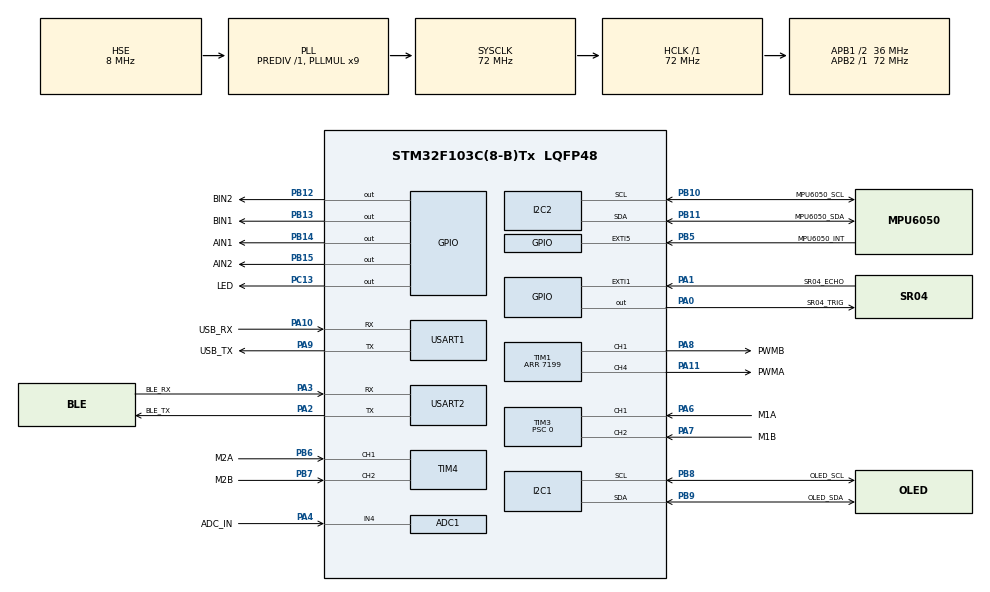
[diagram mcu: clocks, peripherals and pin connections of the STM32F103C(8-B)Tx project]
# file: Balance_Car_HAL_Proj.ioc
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ADC1.Channel-0\#ChannelRegularConversion=ADC_CHANNEL_4
ADC1.NbrOfConversionFlag=1
ADC1.Rank-0\#ChannelRegularConversion=1
ADC1.SamplingTime-0\#ChannelRegularConversion=ADC_SAMPLETIME_1CYCLE_5
ADC1.master=1
Dma.ADC1.0.Direction=DMA_PERIPH_TO_MEMORY
Dma.ADC1.0.Instance=DMA1_Channel1
Dma.ADC1.0.MemDataAlignment=DMA_MDATAALIGN_HALFWORD
Dma.ADC1.0.MemInc=DMA_MINC_ENABLE
Dma.ADC1.0.Mode=DMA_NORMAL
Dma.ADC1.0.PeriphDataAlignment=DMA_PDATAALIGN_HALFWORD
Dma.ADC1.0.PeriphInc=DMA_PINC_DISABLE
Dma.ADC1.0.Priority=DMA_PRIORITY_LOW
Dma.I2C1_TX.2.Direction=DMA_MEMORY_TO_PERIPH
Dma.I2C1_TX.2.Instance=DMA1_Channel6
Dma.I2C1_TX.2.MemDataAlignment=DMA_MDATAALIGN_BYTE
Dma.I2C1_TX.2.MemInc=DMA_MINC_ENABLE
Dma.I2C1_TX.2.Mode=DMA_NORMAL
Dma.I2C1_TX.2.PeriphDataAlignment=DMA_PDATAALIGN_BYTE
Dma.I2C1_TX.2.PeriphInc=DMA_PINC_DISABLE
Dma.I2C1_TX.2.Priority=DMA_PRIORITY_LOW
Dma.I2C2_RX.1.Direction=DMA_PERIPH_TO_MEMORY
Dma.I2C2_RX.1.Instance=DMA1_Channel5
Dma.I2C2_RX.1.MemDataAlignment=DMA_MDATAALIGN_BYTE
Dma.I2C2_RX.1.MemInc=DMA_MINC_ENABLE
Dma.I2C2_RX.1.Mode=DMA_NORMAL
Dma.I2C2_RX.1.PeriphDataAlignment=DMA_PDATAALIGN_BYTE
Dma.I2C2_RX.1.PeriphInc=DMA_PINC_DISABLE
Dma.I2C2_RX.1.Priority=DMA_PRIORITY_HIGH
Dma.Request0=ADC1
Dma.Request1=I2C2_RX
Dma.Request2=I2C1_TX
Dma.Request3=USART1_TX
Dma.Request4=USART2_TX
Dma.USART1_TX.3.Direction=DMA_MEMORY_TO_PERIPH
Dma.USART1_TX.3.Instance=DMA1_Channel4
Dma.USART1_TX.3.MemDataAlignment=DMA_MDATAALIGN_BYTE
Dma.USART1_TX.3.MemInc=DMA_MINC_ENABLE
Dma.USART1_TX.3.Mode=DMA_NORMAL
Dma.USART1_TX.3.PeriphDataAlignment=DMA_PDATAALIGN_BYTE
Dma.USART1_TX.3.PeriphInc=DMA_PINC_DISABLE
Dma.USART1_TX.3.Priority=DMA_PRIORITY_LOW
Dma.USART2_TX.4.Direction=DMA_MEMORY_TO_PERIPH
Dma.USART2_TX.4.Instance=DMA1_Channel7
Dma.USART2_TX.4.MemDataAlignment=DMA_MDATAALIGN_BYTE
Dma.USART2_TX.4.MemInc=DMA_MINC_ENABLE
Dma.USART2_TX.4.Mode=DMA_NORMAL
Dma.USART2_TX.4.PeriphDataAlignment=DMA_PDATAALIGN_BYTE
Dma.USART2_TX.4.PeriphInc=DMA_PINC_DISABLE
Dma.USART2_TX.4.Priority=DMA_PRIORITY_LOW
FREERTOS.Tasks01=InitTask,24,128,initTask,As weak,NULL,Dynamic,NULL,NULL
FREERTOS.configTOTAL_HEAP_SIZE=6656
IWDG.Prescaler=IWDG_PRESCALER_256
Mcu.Family=STM32F1
Mcu.Name=STM32F103C(8-B)Tx
Mcu.Package=LQFP48
NVIC.DMA1_Channel1_IRQn=true\:5\:0\:false\:false\:true\:true\:false\:true\:true
NVIC.DMA1_Channel4_IRQn=true\:5\:0\:false\:false\:true\:true\:false\:true\:true
NVIC.DMA1_Channel5_IRQn=true\:5\:0\:false\:false\:true\:true\:false\:true\:true
NVIC.DMA1_Channel6_IRQn=true\:5\:0\:false\:false\:true\:true\:false\:true\:true
NVIC.DMA1_Channel7_IRQn=true\:5\:0\:false\:false\:true\:true\:false\:true\:true
NVIC.EXTI1_IRQn=true\:5\:0\:false\:false\:true\:true\:true\:true\:true
NVIC.EXTI9_5_IRQn=true\:5\:0\:false\:false\:true\:true\:true\:true\:true
NVIC.I2C1_EV_IRQn=true\:5\:0\:false\:false\:true\:true\:true\:true\:true
NVIC.I2C2_EV_IRQn=true\:5\:0\:true\:false\:true\:true\:true\:true\:true
NVIC.PriorityGroup=NVIC_PRIORITYGROUP_4
NVIC.TIM2_IRQn=true\:15\:0\:false\:false\:true\:false\:false\:true\:true
NVIC.TIM3_IRQn=true\:5\:0\:false\:false\:true\:true\:true\:true\:true
NVIC.TIM4_IRQn=true\:5\:0\:false\:false\:true\:true\:true\:true\:true
NVIC.TimeBase=TIM2_IRQn
NVIC.TimeBaseIP=TIM2
NVIC.USART1_IRQn=true\:5\:0\:false\:false\:true\:true\:true\:true\:true
NVIC.USART2_IRQn=true\:5\:0\:false\:false\:true\:true\:false\:true\:true
PA0-WKUP.GPIO_Label=SR04_TRIG
PA0-WKUP.Signal=GPIO_Output
PA1.GPIO_Label=SR04_ECHO
PA1.GPIO_ModeDefaultEXTI=GPIO_MODE_IT_RISING_FALLING
PA1.Signal=GPXTI1
PA10.GPIO_Label=USB_RX
PA10.Mode=Asynchronous
PA10.Signal=USART1_RX
PA11.GPIO_Label=PWMA
PA11.Signal=S_TIM1_CH4
PA13.Mode=Serial_Wire
PA13.Signal=SYS_JTMS-SWDIO
PA14.Mode=Serial_Wire
PA14.Signal=SYS_JTCK-SWCLK
PA2.GPIO_Label=BLE_TX
PA2.Mode=Asynchronous
PA2.Signal=USART2_TX
PA3.GPIO_Label=BLE_RX
PA3.Mode=Asynchronous
PA3.Signal=USART2_RX
PA4.GPIO_Label=ADC_IN
PA4.Signal=ADCx_IN4
PA6.GPIO_Label=M1A
PA6.Signal=S_TIM3_CH1
PA7.GPIO_Label=M1B
PA7.Signal=S_TIM3_CH2
PA8.GPIO_Label=PWMB
PA8.Signal=S_TIM1_CH1
PA9.GPIO_Label=USB_TX
PA9.Mode=Asynchronous
PA9.Signal=USART1_TX
PB10.GPIO_Label=MPU6050_SCL
PB10.Mode=I2C
PB10.Signal=I2C2_SCL
PB11.GPIO_Label=MPU6050_SDA
PB11.Mode=I2C
PB11.Signal=I2C2_SDA
PB12.GPIO_Label=BIN2
PB12.GPIO_Speed=GPIO_SPEED_FREQ_HIGH
PB12.PinState=GPIO_PIN_RESET
PB12.Signal=GPIO_Output
PB13.GPIO_Label=BIN1
PB13.GPIO_Speed=GPIO_SPEED_FREQ_HIGH
PB13.Signal=GPIO_Output
PB14.GPIO_Label=AIN1
PB14.GPIO_Speed=GPIO_SPEED_FREQ_HIGH
PB14.Signal=GPIO_Output
PB15.GPIO_Label=AIN2
PB15.GPIO_Speed=GPIO_SPEED_FREQ_HIGH
PB15.Signal=GPIO_Output
PB5.GPIO_Label=MPU6050_INT
PB5.Signal=GPXTI5
PB6.GPIO_Label=M2A
PB6.Signal=S_TIM4_CH1
PB7.GPIO_Label=M2B
PB7.Signal=S_TIM4_CH2
PB8.GPIO_Label=OLED_SCL
PB8.Mode=I2C
PB8.Signal=I2C1_SCL
PB9.GPIO_Label=OLED_SDA
PB9.Mode=I2C
PB9.Signal=I2C1_SDA
PC13-TAMPER-RTC.GPIO_Label=LED
PC13-TAMPER-RTC.Signal=GPIO_Output
PD0-OSC_IN.Mode=HSE-External-Oscillator
PD0-OSC_IN.Signal=RCC_OSC_IN
PD1-OSC_OUT.Mode=HSE-External-Oscillator
PD1-OSC_OUT.Signal=RCC_OSC_OUT
ProjectManager.HeapSize=0x200
ProjectManager.StackSize=0x400
ProjectManager.TargetToolchain=CMake
RCC.ADCPresc=RCC_ADCPCLK2_DIV6
RCC.AHBFreq_Value=72000000
RCC.APB1CLKDivider=RCC_HCLK_DIV2
RCC.APB1Freq_Value=36000000
RCC.APB1TimFreq_Value=72000000
RCC.APB2Freq_Value=72000000
RCC.APB2TimFreq_Value=72000000
RCC.HCLKFreq_Value=72000000
RCC.PLLMUL=RCC_PLL_MUL9
RCC.PLLSourceVirtual=RCC_PLLSOURCE_HSE
RCC.SYSCLKFreq_VALUE=72000000
RCC.SYSCLKSource=RCC_SYSCLKSOURCE_PLLCLK
RCC.USBFreq_Value=72000000
SH.ADCx_IN4.0=ADC1_IN4,IN4
SH.S_TIM1_CH1.0=TIM1_CH1,PWM Generation1 CH1
SH.S_TIM1_CH4.0=TIM1_CH4,PWM Generation4 CH4
SH.S_TIM3_CH1.0=TIM3_CH1,Encoder_Interface
SH.S_TIM3_CH2.0=TIM3_CH2,Encoder_Interface
SH.S_TIM4_CH1.0=TIM4_CH1,Encoder_Interface
SH.S_TIM4_CH2.0=TIM4_CH2,Encoder_Interface
TIM1.Channel-PWM\ Generation1\ CH1=TIM_CHANNEL_1
TIM1.Channel-PWM\ Generation4\ CH4=TIM_CHANNEL_4
TIM1.Period=7199
TIM3.EncoderMode=TIM_ENCODERMODE_TI1
TIM3.IC1Filter=10
TIM3.Period=65535
TIM3.Prescaler=0
TIM4.IC1Filter=10
USART1.VirtualMode=VM_ASYNC
USART2.VirtualMode=VM_ASYNC
VP_CRC_VS_CRC.Mode=CRC_Activate
VP_FREERTOS_VS_CMSIS_V2.Mode=CMSIS_V2
VP_IWDG_VS_IWDG.Mode=IWDG_Activate
VP_SYS_VS_tim2.Mode=TIM2
VP_TIM1_VS_ClockSourceINT.Mode=Internal
board=custom

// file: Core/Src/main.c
/* USER CODE BEGIN Header */
/**
  ******************************************************************************
  * @file           : main.c
  * @brief          : Main program body
  ******************************************************************************
  * @attention
  *
  * Copyright (c) 2026 STMicroelectronics.
  * All rights reserved.
  *
  * This software is licensed under terms that can be found in the LICENSE file
  * in the root directory of this software component.
  * If no LICENSE file comes with this software, it is provided AS-IS.
  *
  ******************************************************************************
  */
/* USER CODE END Header */
#include "main.h"
#include "cmsis_os.h"
#include "adc.h"
#include "crc.h"
#include "dma.h"
#include "i2c.h"
#include "iwdg.h"
#include "tim.h"
#include "usart.h"
#include "gpio.h"

void SystemClock_Config(void);
void MX_FREERTOS_Init(void);

int main(void)
{

  /* MCU Configuration--------------------------------------------------------*/

  /* Reset of all peripherals, Initializes the Flash interface and the Systick. */
  HAL_Init();

  /* Configure the system clock */
  SystemClock_Config();

  /* Initialize all configured peripherals */
  MX_GPIO_Init();
  MX_DMA_Init();
  MX_ADC1_Init();
  MX_I2C1_Init();
  MX_I2C2_Init();
  MX_IWDG_Init();
  MX_TIM1_Init();
  MX_TIM3_Init();
  MX_TIM4_Init();
  MX_USART1_UART_Init();
  MX_USART2_UART_Init();
  MX_CRC_Init();

  /* Init scheduler */
  osKernelInitialize();  /* Call init function for freertos objects (in cmsis_os2.c) */
  MX_FREERTOS_Init();

  /* Start scheduler */
  osKernelStart();

  /* We should never get here as control is now taken by the scheduler */

  /* Infinite loop */
  while (1)
  {

  }
}

void SystemClock_Config(void)
{
  RCC_OscInitTypeDef RCC_OscInitStruct = {0};
  RCC_ClkInitTypeDef RCC_ClkInitStruct = {0};
  RCC_PeriphCLKInitTypeDef PeriphClkInit = {0};

  /** Initializes the RCC Oscillators according to the specified parameters
  * in the RCC_OscInitTypeDef structure.
  */
  RCC_OscInitStruct.OscillatorType = RCC_OSCILLATORTYPE_LSI|RCC_OSCILLATORTYPE_HSE;
  RCC_OscInitStruct.HSEState = RCC_HSE_ON;
  RCC_OscInitStruct.HSEPredivValue = RCC_HSE_PREDIV_DIV1;
  RCC_OscInitStruct.HSIState = RCC_HSI_ON;
  RCC_OscInitStruct.LSIState = RCC_LSI_ON;
  RCC_OscInitStruct.PLL.PLLState = RCC_PLL_ON;
  RCC_OscInitStruct.PLL.PLLSource = RCC_PLLSOURCE_HSE;
  RCC_OscInitStruct.PLL.PLLMUL = RCC_PLL_MUL9;
  if (HAL_RCC_OscConfig(&RCC_OscInitStruct) != HAL_OK)
  {
    Error_Handler();
  }

  /** Initializes the CPU, AHB and APB buses clocks
  */
  RCC_ClkInitStruct.ClockType = RCC_CLOCKTYPE_HCLK|RCC_CLOCKTYPE_SYSCLK
                              |RCC_CLOCKTYPE_PCLK1|RCC_CLOCKTYPE_PCLK2;
  RCC_ClkInitStruct.SYSCLKSource = RCC_SYSCLKSOURCE_PLLCLK;
  RCC_ClkInitStruct.AHBCLKDivider = RCC_SYSCLK_DIV1;
  RCC_ClkInitStruct.APB1CLKDivider = RCC_HCLK_DIV2;
  RCC_ClkInitStruct.APB2CLKDivider = RCC_HCLK_DIV1;

  if (HAL_RCC_ClockConfig(&RCC_ClkInitStruct, FLASH_LATENCY_2) != HAL_OK)
  {
    Error_Handler();
  }
  PeriphClkInit.PeriphClockSelection = RCC_PERIPHCLK_ADC;
  PeriphClkInit.AdcClockSelection = RCC_ADCPCLK2_DIV6;
  if (HAL_RCCEx_PeriphCLKConfig(&PeriphClkInit) != HAL_OK)
  {
    Error_Handler();
  }
}

void HAL_TIM_PeriodElapsedCallback(TIM_HandleTypeDef *htim)
{
  if (htim->Instance == TIM2)
  {
    HAL_IncTick();
  }
}

void Error_Handler(void)
{
  __disable_irq();
  while (1)
  {
  }
}

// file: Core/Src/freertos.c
/* USER CODE BEGIN Header */
/**
  ******************************************************************************
  * File Name          : freertos.c
  * Description        : Code for freertos applications
  ******************************************************************************
  * @attention
  *
  * Copyright (c) 2026 STMicroelectronics.
  * All rights reserved.
  *
  * This software is licensed under terms that can be found in the LICENSE file
  * in the root directory of this software component.
  * If no LICENSE file comes with this software, it is provided AS-IS.
  *
  ******************************************************************************
  */
/* USER CODE END Header */

#include "FreeRTOS.h"
#include "task.h"
#include "main.h"
#include "cmsis_os.h"

/* USER CODE BEGIN Includes */
#include "initTask.h"
/* USER CODE END Includes */

/* Definitions for InitTask */
osThreadId_t InitTaskHandle;
const osThreadAttr_t InitTask_attributes = {
  .name = "InitTask",
  .stack_size = 128 * 4,
  .priority = (osPriority_t) osPriorityNormal,
};

void initTask(void *argument);

void MX_FREERTOS_Init(void); /* (MISRA C 2004 rule 8.1) */

void MX_FREERTOS_Init(void) {

  /* Create the thread(s) */
  /* creation of InitTask */
  InitTaskHandle = osThreadNew(initTask, NULL, &InitTask_attributes);

}

__weak void initTask(void *argument)
{
  for(;;)
  {
    osDelay(1);
  }
}
